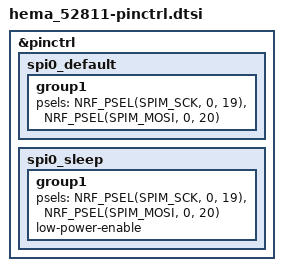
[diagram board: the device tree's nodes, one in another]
/*
 * Copyright (c) 2026 Cremind
 * SPDX-License-Identifier: MIT
 *
 * Hema/Alibaba 52811 panel bus, as documented by EPD-nRF5 (EPD_CFG_52811:
 * MOSI P0.20, SCLK P0.19; hardware/matrix.yaml pins). Write-only SPI: the
 * panel has no MISO line.
 */

&pinctrl {
	spi0_default: spi0_default {
		group1 {
			psels = <NRF_PSEL(SPIM_SCK, 0, 19)>,
				<NRF_PSEL(SPIM_MOSI, 0, 20)>;
		};
	};

	spi0_sleep: spi0_sleep {
		group1 {
			psels = <NRF_PSEL(SPIM_SCK, 0, 19)>,
				<NRF_PSEL(SPIM_MOSI, 0, 20)>;
			low-power-enable;
		};
	};
};
